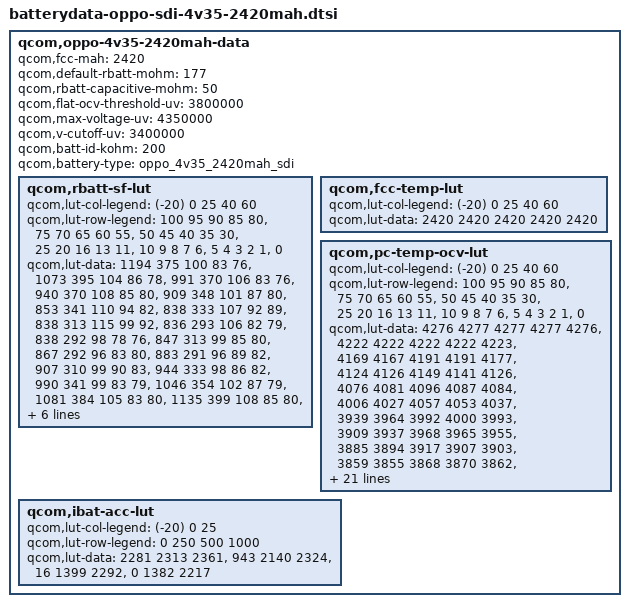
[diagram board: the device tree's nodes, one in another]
/* Copyright (c) 2013, The Linux Foundation. All rights reserved.
 *
 * This program is free software; you can redistribute it and/or modify
 * it under the terms of the GNU General Public License version 2 and
 * only version 2 as published by the Free Software Foundation.
 *
 * This program is distributed in the hope that it will be useful,
 * but WITHOUT ANY WARRANTY; without even the implied warranty of
 * MERCHANTABILITY or FITNESS FOR A PARTICULAR PURPOSE.  See the
 * GNU General Public License for more details.
 */

qcom,oppo-4v35-2420mah-data {
	qcom,fcc-mah = <2420>;
	qcom,default-rbatt-mohm = <177>;
	qcom,rbatt-capacitive-mohm = <50>;
	qcom,flat-ocv-threshold-uv = <3800000>;
	qcom,max-voltage-uv = <4350000>;
	qcom,v-cutoff-uv = <3400000>;
	qcom,batt-id-kohm = <200>;
	qcom,battery-type = "oppo_4v35_2420mah_sdi";

	qcom,rbatt-sf-lut {
		qcom,lut-col-legend = <(-20) 0 25 40 60>;
		qcom,lut-row-legend = <100 95 90 85 80>,
				<75 70 65 60 55>,
				<50 45 40 35 30>,
				<25 20 16 13 11>,
				<10 9 8 7 6>,
				<5 4 3 2 1>,
				<0>;
		qcom,lut-data = <1194 375 100 83 76>,
				<1073 395 104 86 78>,
				<991 370 106 83 76>,
				<940 370 108 85 80>,
				<909 348 101 87 80>,
				<853 341 110 94 82>,
				<838 333 107 92 89>,
				<838 313 115 99 92>,
				<836 293 106 82 79>,
				<838 292 98 78 76>,
				<847 313 99 85 80>,
				<867 292 96 83 80>,
				<883 291 96 89 82>,
				<907 310 99 90 83>,
				<944 333 98 86 82>,
				<990 341 99 83 79>,
				<1046 354 102 87 79>,
				<1081 384 105 83 80>,
				<1135 399 108 85 80>,
				<1163 417 101 87 83>,
				<1186 434 99 86 80>,
				<1204 439 100 89 80>,
				<1245 468 101 89 86>,
				<1268 460 105 92 83>,
				<1297 494 107 89 82>,
				<1318 482 108 89 85>,
				<1345 496 111 89 87>,
				<1371 502 114 92 90>,
				<1435 536 119 116 110>,
				<1693 609 182 708 464>,
				<1975 819 331 824 550>;
	};

	qcom,fcc-temp-lut {
		qcom,lut-col-legend = <(-20) 0 25 40 60>;
		qcom,lut-data = <2420 2420 2420 2420 2420>;
	};

	qcom,pc-temp-ocv-lut {
		qcom,lut-col-legend = <(-20) 0 25 40 60>;
		qcom,lut-row-legend = <100 95 90 85 80>,
				<75 70 65 60 55>,
				<50 45 40 35 30>,
				<25 20 16 13 11>,
				<10 9 8 7 6>,
				<5 4 3 2 1>,
				<0>;
		qcom,lut-data = <4276 4277 4277 4277 4276>,
				<4222 4222 4222 4222 4223>,
				<4169 4167 4191 4191 4177>,
				<4124 4126 4149 4141 4126>,
				<4076 4081 4096 4087 4084>,
				<4006 4027 4057 4053 4037>,
				<3939 3964 3992 4000 3993>,
				<3909 3937 3968 3965 3955>,
				<3885 3894 3917 3907 3903>,
				<3859 3855 3868 3870 3862>,
				<3834 3829 3841 3841 3841>,
				<3813 3810 3819 3825 3819>,
				<3796 3795 3801 3809 3804>,
				<3787 3783 3788 3792 3788>,
				<3777 3769 3773 3770 3759>,
				<3765 3761 3756 3750 3738>,
				<3747 3743 3738 3736 3715>,
				<3731 3723 3714 3708 3694>,
				<3719 3698 3695 3690 3676>,
				<3714 3694 3687 3689 3676>,
				<3711 3692 3686 3687 3673>,
				<3709 3692 3685 3687 3672>,
				<3702 3690 3684 3682 3668>,
				<3697 3688 3683 3677 3661>,
				<3689 3686 3670 3658 3639>,
				<3675 3671 3643 3620 3605>,
				<3655 3641 3604 3576 3562>,
				<3628 3602 3553 3520 3506>,
				<3538 3486 3488 3334 3329>,
				<3380 3384 3233 3143 3151>,
				<3000 3000 3000 3000 3000>;
	};

	qcom,ibat-acc-lut {
		qcom,lut-col-legend = <(-20) 0 25>;
		qcom,lut-row-legend = <0 250 500 1000>;
		qcom,lut-data = <2281 2313 2361>,
				<943 2140 2324>,
				<16 1399 2292>,
				<0 1382 2217>;
	};
};
